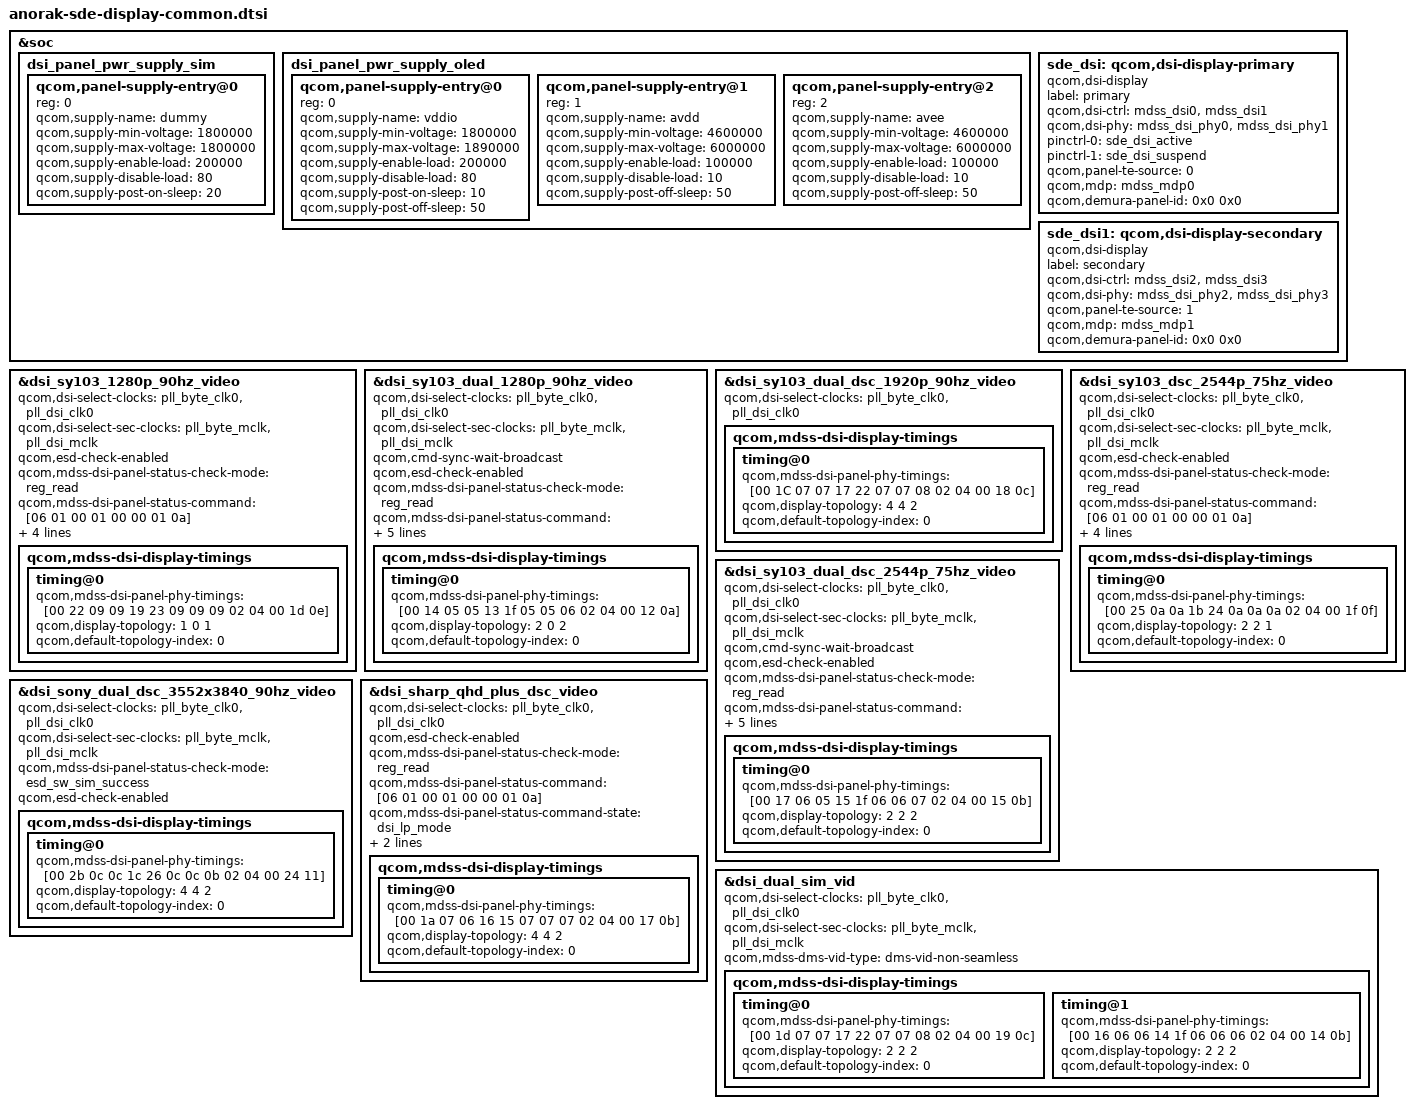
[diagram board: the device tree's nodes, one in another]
#include "dsi-panel-sy103-1280p-video.dtsi"
#include "dsi-panel-sy103-dualmipi-1280p-video.dtsi"
#include "dsi-panel-sy103-dsc-2544p-video.dtsi"
#include "dsi-panel-sy103-dualmipi-dsc-2544p-video.dtsi"
#include "dsi-panel-sy103-dualmipi-dsc-1920p-video.dtsi"
#include "dsi-panel-sony-dualmipi-dsc-3552x3840-video.dtsi"
#include "dsi-panel-sharp-dsc-qhd-plus-video.dtsi"
#include "dsi-panel-sim-dualmipi-video.dtsi"

#include "anorak-sde-display-pinctrl.dtsi"

&soc {
	dsi_panel_pwr_supply_sim: dsi_panel_pwr_supply_sim {
		#address-cells = <1>;
		#size-cells = <0>;

		qcom,panel-supply-entry@0 {
			reg = <0>;
			qcom,supply-name = "dummy";
			qcom,supply-min-voltage = <1800000>;
			qcom,supply-max-voltage = <1800000>;
			qcom,supply-enable-load = <200000>;
			qcom,supply-disable-load = <80>;
			qcom,supply-post-on-sleep = <20>;
		};
	};

	dsi_panel_pwr_supply_oled: dsi_panel_pwr_supply_oled {
		#address-cells = <1>;
		#size-cells = <0>;

		qcom,panel-supply-entry@0 {
			reg = <0>;
			qcom,supply-name = "vddio";
			qcom,supply-min-voltage = <1800000>;
			qcom,supply-max-voltage = <1890000>;
			qcom,supply-enable-load = <200000>;
			qcom,supply-disable-load = <80>;
			qcom,supply-post-on-sleep = <10>;
			qcom,supply-post-off-sleep = <50>;
		};

		qcom,panel-supply-entry@1 {
			reg = <1>;
			qcom,supply-name = "avdd";
			qcom,supply-min-voltage = <4600000>;
			qcom,supply-max-voltage = <6000000>;
			qcom,supply-enable-load = <100000>;
			qcom,supply-disable-load = <10>;
			qcom,supply-post-off-sleep = <50>;
		};

		qcom,panel-supply-entry@2 {
			reg = <2>;
			qcom,supply-name = "avee";
			qcom,supply-min-voltage = <4600000>;
			qcom,supply-max-voltage = <6000000>;
			qcom,supply-enable-load = <100000>;
			qcom,supply-disable-load = <10>;
			qcom,supply-post-off-sleep = <50>;
		};
	};

	sde_dsi: qcom,dsi-display-primary {
		compatible = "qcom,dsi-display";
		label = "primary";

		qcom,dsi-ctrl = <&mdss_dsi0 &mdss_dsi1>;
		qcom,dsi-phy = <&mdss_dsi_phy0 &mdss_dsi_phy1>;

		pinctrl-names = "panel_active", "panel_suspend";
		pinctrl-0 = <&sde_dsi_active>;
		pinctrl-1 = <&sde_dsi_suspend>;

		qcom,panel-te-source = <0>;

		qcom,mdp = <&mdss_mdp0>;
		qcom,demura-panel-id = <0x0 0x0>;
	};

	sde_dsi1: qcom,dsi-display-secondary {
		compatible = "qcom,dsi-display";
		label = "secondary";

		qcom,dsi-ctrl = <&mdss_dsi2 &mdss_dsi3>;
		qcom,dsi-phy = <&mdss_dsi_phy2 &mdss_dsi_phy3>;

		qcom,panel-te-source = <1>;

		qcom,mdp = <&mdss_mdp1>;
		qcom,demura-panel-id = <0x0 0x0>;
	};
};

/* PHY TIMINGS REVISION YK with reduced margins*/
&dsi_sy103_1280p_90hz_video {
	qcom,dsi-select-clocks = "pll_byte_clk0", "pll_dsi_clk0";
	qcom,dsi-select-sec-clocks = "pll_byte_mclk", "pll_dsi_mclk";

	qcom,esd-check-enabled;
	qcom,mdss-dsi-panel-status-check-mode = "reg_read";
	qcom,mdss-dsi-panel-status-command = [06 01 00 01 00 00 01 0a];
	qcom,mdss-dsi-panel-status-command-state = "dsi_hs_mode";
	qcom,mdss-dsi-panel-status-value = <0x9c>;
	qcom,mdss-dsi-panel-status-read-length = <1>;
	qcom,mdss-dsi-display-timings {
                timing@0 {
                        qcom,mdss-dsi-panel-phy-timings = [00 22 09 09 19 23 09
				09 09 02 04 00 1d 0e];
                        qcom,display-topology = <1 0 1>;
                        qcom,default-topology-index = <0>;
                };
        };
};

&dsi_sy103_dual_1280p_90hz_video {
	qcom,dsi-select-clocks = "pll_byte_clk0", "pll_dsi_clk0";
	qcom,dsi-select-sec-clocks = "pll_byte_mclk", "pll_dsi_mclk";

	qcom,cmd-sync-wait-broadcast;
	qcom,esd-check-enabled;
	qcom,mdss-dsi-panel-status-check-mode = "reg_read";
	qcom,mdss-dsi-panel-status-command = [06 01 00 01 00 00 01 0a];
	qcom,mdss-dsi-panel-status-command-state = "dsi_hs_mode";
	qcom,mdss-dsi-panel-status-value = <0x9c>;
	qcom,mdss-dsi-panel-status-read-length = <1>;
	qcom,mdss-dsi-display-timings {
		timing@0 {
			qcom,mdss-dsi-panel-phy-timings = [00 14 05 05 13 1f 05
				05 06 02 04 00 12 0a];
			qcom,display-topology = <2 0 2>;
			qcom,default-topology-index = <0>;
		};
	};
};

&dsi_sy103_dual_dsc_1920p_90hz_video {
	qcom,dsi-select-clocks = "pll_byte_clk0", "pll_dsi_clk0";

	qcom,mdss-dsi-display-timings {
		timing@0 {
			qcom,mdss-dsi-panel-phy-timings = [00 1C 07 07 17 22 07
				07 08 02 04 00 18 0c];
			qcom,display-topology = <4 4 2>;
			qcom,default-topology-index = <0>;
		};
	};
};

&dsi_sy103_dsc_2544p_75hz_video {
	qcom,dsi-select-clocks = "pll_byte_clk0", "pll_dsi_clk0";
	qcom,dsi-select-sec-clocks = "pll_byte_mclk", "pll_dsi_mclk";

	qcom,esd-check-enabled;
	qcom,mdss-dsi-panel-status-check-mode = "reg_read";
	qcom,mdss-dsi-panel-status-command = [06 01 00 01 00 00 01 0a];
	qcom,mdss-dsi-panel-status-command-state = "dsi_hs_mode";
	qcom,mdss-dsi-panel-status-value = <0x9c>;
	qcom,mdss-dsi-panel-status-read-length = <1>;
	qcom,mdss-dsi-display-timings {
                timing@0 {
			qcom,mdss-dsi-panel-phy-timings = [00 25 0a 0a 1b 24 0a
				0a 0a 02 04 00 1f 0f];
                        qcom,display-topology = <2 2 1>;
                        qcom,default-topology-index = <0>;
                };
        };
};

&dsi_sy103_dual_dsc_2544p_75hz_video {
	qcom,dsi-select-clocks = "pll_byte_clk0", "pll_dsi_clk0";
	qcom,dsi-select-sec-clocks = "pll_byte_mclk", "pll_dsi_mclk";

	qcom,cmd-sync-wait-broadcast;
	qcom,esd-check-enabled;
	qcom,mdss-dsi-panel-status-check-mode = "reg_read";
	qcom,mdss-dsi-panel-status-command = [06 01 00 01 00 00 01 0a];
	qcom,mdss-dsi-panel-status-command-state = "dsi_hs_mode";
	qcom,mdss-dsi-panel-status-value = <0x9c>;
	qcom,mdss-dsi-panel-status-read-length = <1>;
	qcom,mdss-dsi-display-timings {
		timing@0 {
			qcom,mdss-dsi-panel-phy-timings = [00 17 06 05 15 1f 06
				06 07 02 04 00 15 0b];
			qcom,display-topology = <2 2 2>;
			qcom,default-topology-index = <0>;
		};
	};
};

&dsi_sony_dual_dsc_3552x3840_90hz_video {
	qcom,dsi-select-clocks = "pll_byte_clk0", "pll_dsi_clk0";
	qcom,dsi-select-sec-clocks = "pll_byte_mclk", "pll_dsi_mclk";

	qcom,mdss-dsi-panel-status-check-mode = "esd_sw_sim_success";
	qcom,esd-check-enabled;

	qcom,mdss-dsi-display-timings {
		timing@0 {
			qcom,mdss-dsi-panel-phy-timings = [00 2b 0c 0c 1c 26 0c
				0c 0b 02 04 00 24 11];
			qcom,display-topology = <4 4 2>;
			qcom,default-topology-index = <0>;
		};
	};
};

&dsi_sharp_qhd_plus_dsc_video {
	qcom,dsi-select-clocks = "pll_byte_clk0", "pll_dsi_clk0";

	qcom,esd-check-enabled;
	qcom,mdss-dsi-panel-status-check-mode = "reg_read";
	qcom,mdss-dsi-panel-status-command = [06 01 00 01 00 00 01 0a];
	qcom,mdss-dsi-panel-status-command-state = "dsi_lp_mode";
	qcom,mdss-dsi-panel-status-value = <0x1c>;
	qcom,mdss-dsi-panel-status-read-length = <1>;

	qcom,mdss-dsi-display-timings {
		timing@0 { /* 120 FPS */
			qcom,mdss-dsi-panel-phy-timings = [00 1a 07 06 16 15 07
				07 07 02 04 00 17 0b];
			qcom,display-topology = <4 4 2>;
			qcom,default-topology-index = <0>;
		};
	};
};

&dsi_dual_sim_vid {
	qcom,dsi-select-clocks = "pll_byte_clk0", "pll_dsi_clk0";
	qcom,dsi-select-sec-clocks = "pll_byte_mclk", "pll_dsi_mclk";
	qcom,mdss-dms-vid-type = "dms-vid-non-seamless";

	qcom,mdss-dsi-display-timings {
		timing@0 {
			qcom,mdss-dsi-panel-phy-timings = [00 1d 07 07 17 22 07
				07 08 02 04 00 19 0c];
			qcom,display-topology = <2 2 2>;
			qcom,default-topology-index = <0>;
		};
		timing@1 {
			qcom,mdss-dsi-panel-phy-timings = [00 16 06 06 14 1f 06
				06 06 02 04 00 14 0b];
			qcom,display-topology = <2 2 2>;
			qcom,default-topology-index = <0>;
		};
	};
};
